# PY32M070Cxx register map
Vendor: Puya; Series: PY32M; File version: 1.0.0
CPU: CM0+ r0p1, little endian, no MPU, no FPU, 4 interrupt priority bits
Registers are 32-bit, read-write, reset 0x0 unless marked. A register's access mark holds for its fields unless they carry their own. Offsets are from the block's base; [hi:lo] are bit positions; {n}, {i} and the like mark numbered series; 'fields as' and 'values as' point back to an identical list.

## EXTI — External interrupt/event controller
Base 0x40021800
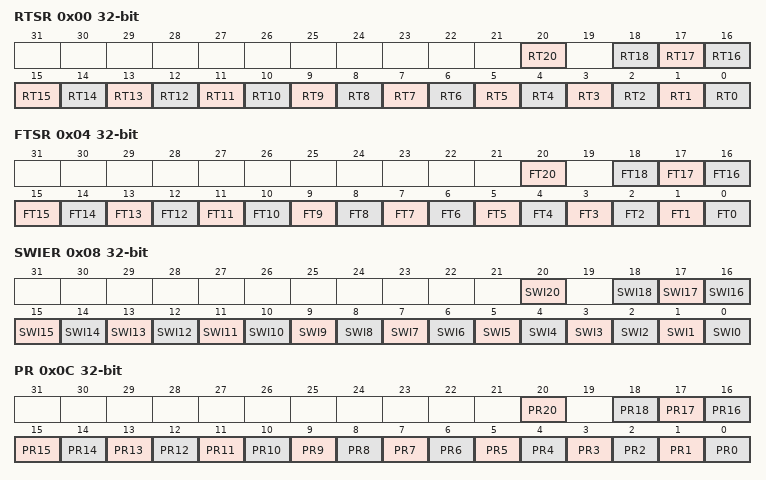
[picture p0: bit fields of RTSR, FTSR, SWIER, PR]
0x00 RTSR — EXTI rising trigger selection register
  [20] RT20 — Rising trigger event configuration bit of Configurable Event input
  [n] RT{n} (n=0..18) — Rising trigger event configuration bit of Configurable Event input
0x04 FTSR — EXTI falling trigger selection register
  [20] FT20 — Falling trigger event configuration bit of Configurable Event input
  [n] FT{n} (n=0..18) — Falling trigger event configuration bit of Configurable Event input
0x08 SWIER — EXTI software interrupt event register
  [20] SWI20 — Rising trigger event configuration bit of Configurable Event input
  [n] SWI{n} (n=0..18) — Rising trigger event configuration bit of Configurable Event input
0x0C PR — EXTI pending register
  [20] PR20 — configurable event inputs x rising edge Pending bit.
  [n] PR{n} (n=14..18) — configurable event inputs x rising edge Pending bit.
  [13] PR13 — configurable event inputs x rising edge Pending bit
  [n] PR{n} (n=0..12) — configurable event inputs x rising edge Pending bit.
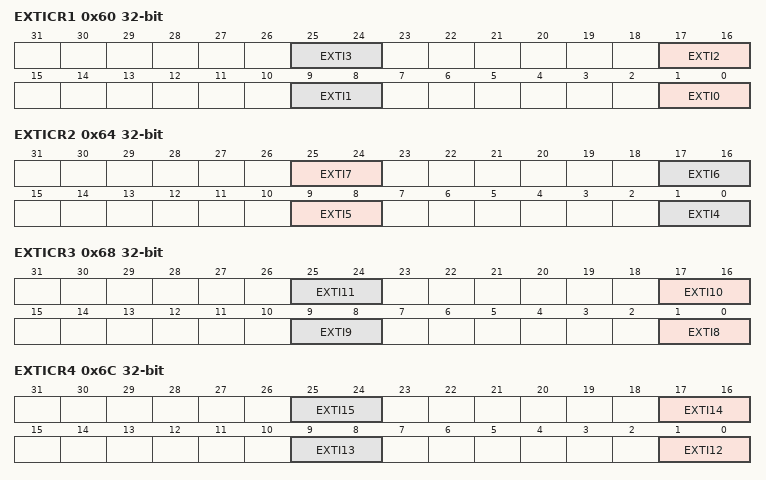
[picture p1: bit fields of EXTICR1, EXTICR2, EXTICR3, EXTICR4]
0x60 EXTICR1 — EXTI external interrupt selection register
  [all] fields
    1=0; 2=1
  [8n+1:8n] EXTI{n} (n=0..3) — GPIO port selection
0x64 EXTICR2 — EXTI external interrupt selection register
  [25:24] EXTI7 — GPIO port selection
  [17:16] EXTI6 — GPIO port selection
  [9:8] EXTI5 — GPIO port selection
  [1:0] EXTI4 — GPIO port selection
    1=0; 2=1
0x68 EXTICR3 — EXTI external interrupt selection register
  [all] fields
    1=0; 2=1
  [8n-63:8n-64] EXTI{n} (n=8..11) — GPIO port selection
0x6C EXTICR4 — EXTI external interrupt selection register
  [all] fields
    1=0; 2=1
  [8n-95:8n-96] EXTI{n} (n=12..15) — GPIO port selection
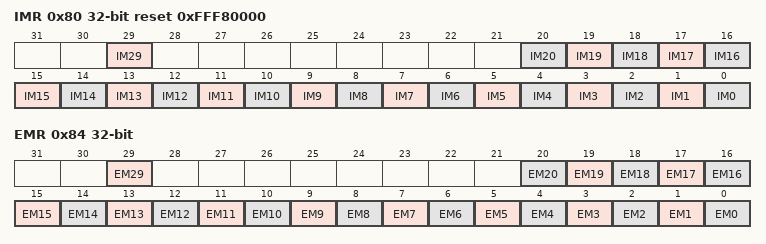
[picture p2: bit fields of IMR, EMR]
0x80 IMR reset 0xFFF80000 — EXTI CPU wakeup with interrupt mask register
  [29] IM29 — CPU wakeup with interrupt mask on event input
  [n] IM{n} (n=0..20) — CPU wakeup with interrupt mask on event input
0x84 EMR — EXTI CPU wakeup with event mask register
  [29] EM29 — CPU wakeup with event mask on event input
  [n] EM{n} (n=0..20) — CPU wakeup with event mask on event input

## FLASH
Base 0x40022000
0x00 ACR reset 0x500
  [1:0] LATENCY
    1=0; 2=1
0x08 KEYR wo
  [31:0] KEY
0x0C OPTKEYR wo
  [31:0] OPTKEY
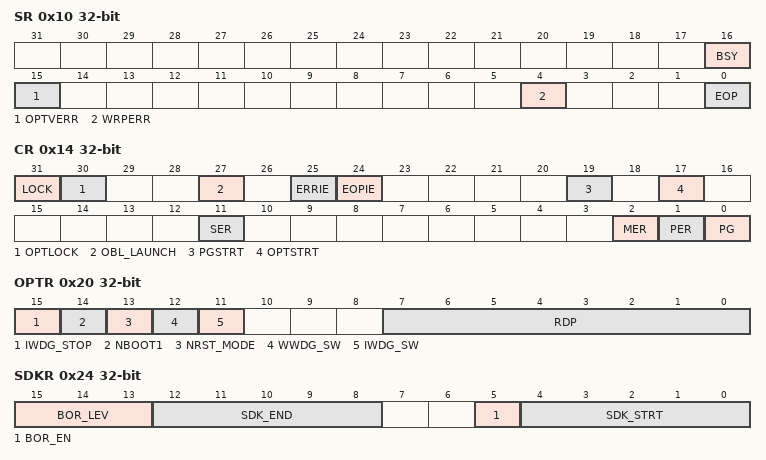
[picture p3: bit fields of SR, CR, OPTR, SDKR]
0x10 SR
  [16] BSY ro, [15] OPTVERR, [4] WRPERR, [0] EOP
0x14 CR
  [31] LOCK, [30] OPTLOCK, [27] OBL_LAUNCH, [25] ERRIE, [24] EOPIE, [19] PGSTRT, [17] OPTSTRT, [11] SER, [2] MER, [1] PER, [0] PG
0x20 OPTR ro
  [15] IWDG_STOP
  [14] NBOOT1
  [13] NRST_MODE
  [12] WWDG_SW
  [11] IWDG_SW
  [7:0] RDP
    85=LEVEL_1; 170=LEVEL_0
0x24 SDKR ro
  [15:13] BOR_LEV
    1=0; 2=1; 4=2
  [12:8] SDK_END
    1=0; 2=1; 4=2; 8=3; 16=4
  [5] BOR_EN
  [4:0] SDK_STRT
    1=0; 2=1; 4=2; 8=3; 16=4
0x2C WRPR
  [15:0] WRP
    1=0; 2=1; 4=2; 8=3; 16=4; 32=5; 64=6; 128=7; 0x100=8; 0x200=9; 0x400=10; 0x800=11; 0x1000=12; 0x2000=13; 0x4000=14; 0x8000=15
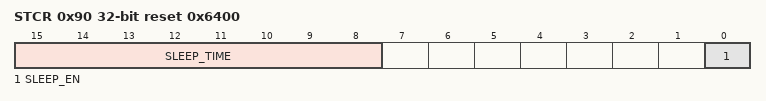
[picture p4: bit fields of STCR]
0x90 STCR reset 0x6400
  [15:8] SLEEP_TIME, [0] SLEEP_EN
0x100 TS0 reset 0xB4
  [7:0] TS0
    1=0; 2=1; 4=2; 8=3; 16=4; 32=5; 64=6; 128=7
0x104 TS1 reset 0x1B0
  [8:0] TS1
    1=0; 2=1; 4=2; 8=3; 16=4; 32=5; 64=6; 128=7; 0x100=8
0x108 TS2P reset 0xB4
  [7:0] TS2P
    1=0; 2=1; 4=2; 8=3; 16=4; 32=5; 64=6; 128=7
0x10C TPS3 reset 0x6C0
  [10:0] TPS3
    1=0; 2=1; 4=2; 8=3; 16=4; 32=5; 64=6; 128=7; 0x100=8; 0x200=9; 0x400=10
0x110 TS3 reset 0xB4
  [7:0] TS3
    1=0; 2=1; 4=2; 8=3; 16=4; 32=5; 64=6; 128=7
0x114 PERTPE reset 0xEA60
  [16:0] PERTPE
    1=0; 2=1; 4=2; 8=3; 16=4; 32=5; 64=6; 128=7; 0x100=8; 0x200=9; 0x400=10; 0x800=11; 0x1000=12; 0x2000=13; 0x4000=14; 0x8000=15; 0x10000=16
0x118 SMERTPE reset 0xFD20
  [16:0] SMERTPE
    values as PERTPE.PERTPE
0x11C PRGTPE reset 0x8CA0
  [15:0] PRGTPE
    values as WRPR.WRP
0x120 PRETPE reset 0x12C0
  [13:0] PRETPE
    1=0; 2=1; 4=2; 8=3; 16=4; 32=5; 64=6; 128=7; 0x100=8; 0x200=9; 0x400=10; 0x800=11; 0x1000=12; 0x2000=13
